# GD32L235x register map
File version: 1.0
CPU: CM23 r1p0, little endian, no MPU, no FPU, 2 interrupt priority bits
Registers are 32-bit, read-write, reset 0x0 unless marked. A register's access mark holds for its fields unless they carry their own. Offsets are from the block's base; [hi:lo] are bit positions.

## RCU — Reset and clock unit
Base 0x40021000
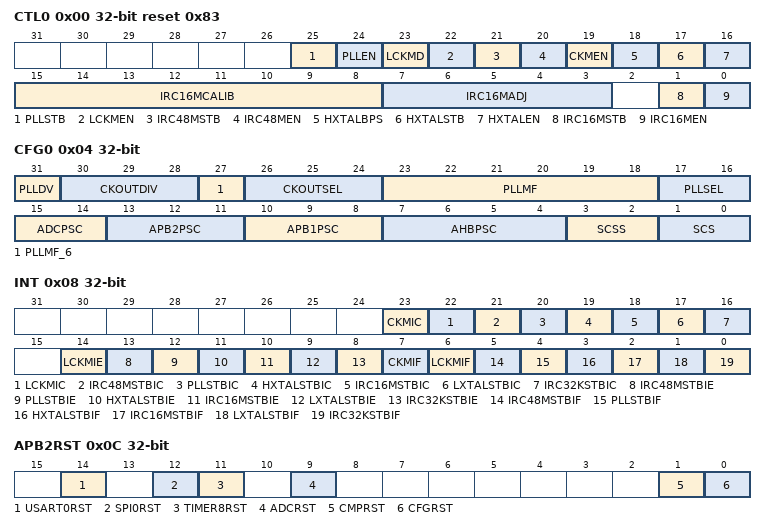
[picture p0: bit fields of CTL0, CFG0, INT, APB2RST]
0x00 CTL0 access per field reset 0x83 — Control register 0
  [25] PLLSTB ro — PLL Clock Stabilization Flag
  [24] PLLEN rw — PLL enable
  [23] LCKMD rw — LXTAL clock failure detection
  [22] LCKMEN rw — LXTAL clock monitor enable
  [21] IRC48MSTB rw — IRC48M oscillator stabilization flag
  [20] IRC48MEN rw — Internal high speed oscillator enable
  [19] CKMEN rw — HXTAL Clock Monitor Enable
  [18] HXTALBPS rw — External crystal oscillator (HXTAL) clock bypass mode enable
  [17] HXTALSTB ro — External crystal oscillator (HXTAL) clock stabilization flag
  [16] HXTALEN rw — External High Speed oscillator Enable
  [15:8] IRC16MCALIB ro — High Speed Internal Oscillator calibration value register
  [7:3] IRC16MADJ rw — High Speed Internal Oscillator clock trim adjust value
  [1] IRC16MSTB ro — IRC8M High Speed Internal Oscillator stabilization Flag
  [0] IRC16MEN rw — Internal High Speed oscillator Enable
0x04 CFG0 access per field — Clock configuration register 0 (RCU_CFG0)
  [31] PLLDV rw — The CK_PLL divide by 1 or 2 for CK_OUT
  [30:28] CKOUTDIV rw — The CK_OUT divider which the CK_OUT frequency can be reduced
  [27] PLLMF_6 rw — Bit 6 of PLLMF
  [26:24] CKOUTSEL rw — CK_OUT Clock Source Selection
  [23:18] PLLMF rw — PLL multiply factor
  [17:16] PLLSEL rw — PLL Clock Source Selection
  [15:14] ADCPSC rw — ADC clock prescaler selection
  [13:11] APB2PSC rw — APB2 prescaler selection
  [10:8] APB1PSC rw — APB1 prescaler selection
  [7:4] AHBPSC rw — AHB prescaler selection
  [3:2] SCSS ro — System clock switch status
  [1:0] SCS rw — System clock switch
0x08 INT access per field — Clock interrupt register (RCU_INT)
  [23] CKMIC wo — HXTAL Clock Stuck Interrupt Clear
  [22] LCKMIC wo — LXTAL clock stuck interrupt clear
  [21] IRC48MSTBIC wo — IRC48M stabilization Interrupt Clear
  [20] PLLSTBIC wo — PLL stabilization Interrupt Clear
  [19] HXTALSTBIC wo — HXTAL Stabilization Interrupt Clear
  [18] IRC16MSTBIC wo — IRC16M Stabilization Interrupt Clear
  [17] LXTALSTBIC wo — LXTAL Stabilization Interrupt Clear
  [16] IRC32KSTBIC wo — IRC32K Stabilization Interrupt Clear
  [14] LCKMIE wo — LXTAL clock stuck interrupt enable
  [13] IRC48MSTBIE rw — IRC48M Stabilization Interrupt Enable
  [12] PLLSTBIE rw — PLL Stabilization Interrupt Enable
  [11] HXTALSTBIE rw — HXTAL Stabilization Interrupt Enable
  [10] IRC16MSTBIE rw — IRC16M Stabilization Interrupt Enable
  [9] LXTALSTBIE rw — LXTAL Stabilization Interrupt Enable
  [8] IRC32KSTBIE rw — IRC32K Stabilization interrupt enable
  [7] CKMIF ro — HXTAL Clock Stuck Interrupt Flag
  [6] LCKMIF ro — LXTAL clock stuck interrupt flag
  [5] IRC48MSTBIF ro — IRC48M stabilization interrupt flag
  [4] PLLSTBIF ro — PLL stabilization interrupt flag
  [3] HXTALSTBIF ro — HXTAL stabilization interrupt flag
  [2] IRC16MSTBIF ro — IRC16M stabilization interrupt flag
  [1] LXTALSTBIF ro — LXTAL stabilization interrupt flag
  [0] IRC32KSTBIF ro — IRC32K stabilization interrupt flag
0x0C APB2RST — APB2 reset register (RCU_APB2RST)
  [14] USART0RST — USART0 Reset
  [12] SPI0RST — SPI0 Reset
  [11] TIMER8RST — TIMER8 reset
  [9] ADCRST — ADC reset
  [1] CMPRST — Comparator reset
  [0] CFGRST — System configuration reset
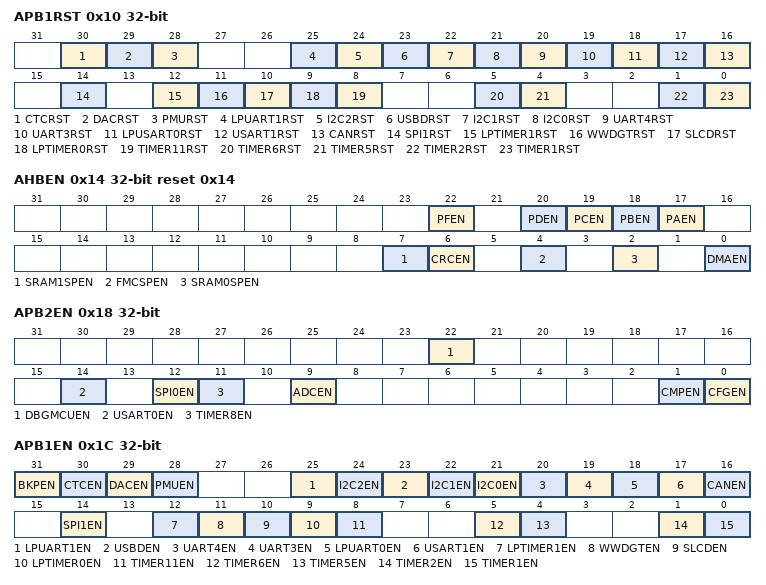
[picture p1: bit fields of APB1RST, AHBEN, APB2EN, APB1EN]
0x10 APB1RST — APB1 reset register (RCU_APB1RST)
  [30] CTCRST — CTC reset
  [29] DACRST — DAC reset
  [28] PMURST — Power control reset
  [25] LPUART1RST — LPUART1 reset
  [24] I2C2RST — I2C2 reset
  [23] USBDRST — USBD reset
  [22] I2C1RST — I2C1 reset
  [21] I2C0RST — I2C0 reset
  [20] UART4RST — UART4 reset
  [19] UART3RST — UART3 reset
  [18] LPUSART0RST — LPUSART0 reset
  [17] USART1RST — USART1 reset
  [16] CANRST — CAN reset
  [14] SPI1RST — SPI1 reset
  [12] LPTIMER1RST — LPTIMER1 timer reset
  [11] WWDGTRST — Window watchdog timer reset
  [10] SLCDRST — SLCD reset
  [9] LPTIMER0RST — LPTIMER0 timer reset
  [8] TIMER11RST — TIMER11 timer reset
  [5] TIMER6RST — TIMER6 timer reset
  [4] TIMER5RST — TIMER5 timer reset
  [1] TIMER2RST — TIMER2 timer reset
  [0] TIMER1RST — TIMER1 timer reset
0x14 AHBEN reset 0x14 — AHB enable register (RCU_AHBEN)
  [22] PFEN — GPIO port F clock enable
  [20] PDEN — GPIO port D clock enable
  [19] PCEN — GPIO port C clock enable
  [18] PBEN — GPIO port B clock enable
  [17] PAEN — GPIO port A clock enable
  [7] SRAM1SPEN — SRAM1 interface clock enable
  [6] CRCEN — CRC clock enable
  [4] FMCSPEN — FMC clock during sleep mode enable
  [2] SRAM0SPEN — SRAM0 interface clock during sleep mode enable
  [0] DMAEN — DMA clock enable
0x18 APB2EN — APB2 enable register (RCU_APB2EN)
  [22] DBGMCUEN — DBGMCU clock enable
  [14] USART0EN — USART0 clock enable
  [12] SPI0EN — SPI0 clock enable
  [11] TIMER8EN — TIMER8 timer clock enable
  [9] ADCEN — ADC interface clock enable
  [1] CMPEN — Comparator clock enable
  [0] CFGEN — System configuration clock enable
0x1C APB1EN — APB1 enable register (RCU_APB1EN)
  [31] BKPEN — BKP (RTC) clock enable
  [30] CTCEN — CTC clock enable
  [29] DACEN — DAC clock enable
  [28] PMUEN — Power interface clock enable
  [25] LPUART1EN — LPUART1 clock enable
  [24] I2C2EN — I2C2 clock enable
  [23] USBDEN — USBDclock enable
  [22] I2C1EN — I2C1 clock enable
  [21] I2C0EN — I2C0 clock enable
  [20] UART4EN — UART4 clock enable
  [19] UART3EN — UART3 clock enable
  [18] LPUART0EN — LPUART0 clock enable
  [17] USART1EN — USART1 clock enable
  [16] CANEN — CAN clock enable
  [14] SPI1EN — SPI1 clock enable
  [12] LPTIMER1EN — LPTIMER1EN clock enable
  [11] WWDGTEN — Window watchdog timer clock enable
  [10] SLCDEN — SLCD clock enable
  [9] LPTIMER0EN — LPTIMER0 clock enable
  [8] TIMER11EN — TIMER11EN clock enable
  [5] TIMER6EN — TIMER6EN clock enable
  [4] TIMER5EN — TIMER5 timer clock enable
  [1] TIMER2EN — TIMER2 timer clock enable
  [0] TIMER1EN — TIMER1 timer clock enable
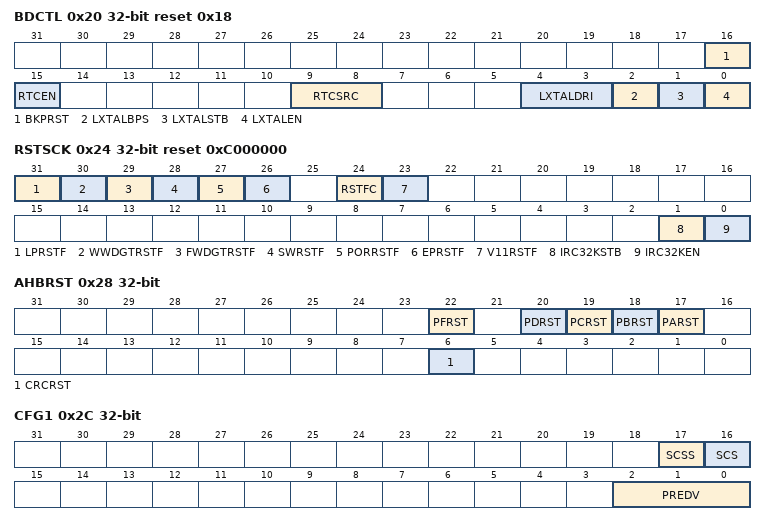
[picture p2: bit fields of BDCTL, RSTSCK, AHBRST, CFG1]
0x20 BDCTL access per field reset 0x18 — Backup domain control register (RCU_BDCTL)
  [16] BKPRST rw — Backup domain reset
  [15] RTCEN rw — RTC clock enable
  [9:8] RTCSRC rw — RTC clock entry selection
  [4:3] LXTALDRI rw — LXTAL drive capability
  [2] LXTALBPS rw — LXTAL bypass mode enable
  [1] LXTALSTB ro — External low-speed oscillator stabilization
  [0] LXTALEN rw — LXTAL enable
0x24 RSTSCK access per field reset 0xC000000 — Reset source /clock register (RCU_RSTSCK)
  [31] LPRSTF ro — Low-power reset flag
  [30] WWDGTRSTF ro — Window watchdog timer reset flag
  [29] FWDGTRSTF ro — Free Watchdog timer reset flag
  [28] SWRSTF ro — Software reset flag
  [27] PORRSTF ro — Power reset flag
  [26] EPRSTF ro — External PIN reset flag
  [24] RSTFC rw — Reset flag clear
  [23] V11RSTF ro — V11 domain Power reset flag
  [1] IRC32KSTB ro — IRC32K stabilization
  [0] IRC32KEN rw — IRC32K enable
0x28 AHBRST — AHB reset register
  [22] PFRST — GPIO port F reset
  [20] PDRST — GPIO port D reset
  [19] PCRST — GPIO port C reset
  [18] PBRST — GPIO port B reset
  [17] PARST — GPIO port A reset
  [6] CRCRST — CRC reset
0x2C CFG1 — Configuration register 1
  [17] SCSS — Bit 2 of SSCS
  [16] SCS — Bit 2 of SCS
  [2:0] PREDV — CK_HXTAL divider previous PLL
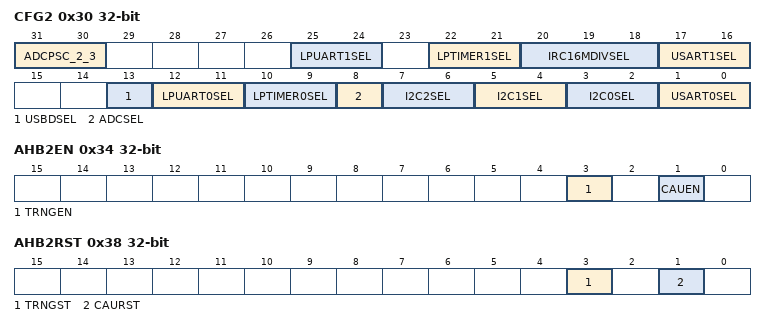
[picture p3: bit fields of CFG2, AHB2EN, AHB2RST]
0x30 CFG2 — Configuration register 2
  [31:30] ADCPSC_2_3 — Bit 2 and Bit 3 of ADCPSC
  [25:24] LPUART1SEL — LPUART1 clock source selection
  [22:21] LPTIMER1SEL — LPUART1 clock source selection
  [20:18] IRC16MDIVSEL — CK_IRC16M divided clock selection
  [17:16] USART1SEL — CK_USART1 clock source selection
  [13] USBDSEL — USBD clock source selection
  [12:11] LPUART0SEL — LPUART0 clock source selection
  [10:9] LPTIMER0SEL — LPTIMER0 clock source selection
  [8] ADCSEL — CK_ADC clock source selection
  [7:6] I2C2SEL — I2C2 clock source selection
  [5:4] I2C1SEL — I2C1 clock source selection
  [3:2] I2C0SEL — I2C0 clock source selection
  [1:0] USART0SEL — CK_USART0 clock source selection
0x34 AHB2EN — AHB2 enable register
  [3] TRNGEN — TRNG clock enable
  [1] CAUEN — CAU clock enable
0x38 AHB2RST — AHB2 reset register
  [3] TRNGST — TRNG reset
  [1] CAURST — CAU reset
0x100 VKEY wo — Voltage key register
  [31:0] KEY — The key of RCU_DSV register
0x128 LPLDO reset 0x7 — Low power mode LDO voltage register
  [3:0] LPLDOSEL — Deep-sleep mode LDO voltage select
0x12C LPB reset 0x7 — Low power bandgap mode register
  [2:0] LPBMSEL — Low power mode selection signal
